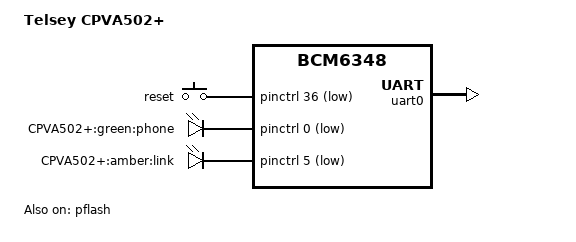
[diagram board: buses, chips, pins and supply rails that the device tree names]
/dts-v1/;

#include "bcm6348.dtsi"

#include <dt-bindings/input/input.h>

/ {
	model = "Telsey CPVA502+";
	compatible = "telsey,cpva502+", "brcm,bcm6348";

	chosen {
		bootargs = "root=/dev/mtdblock2 rootfstype=squashfs,jffs2 noinitrd console=ttyS0,115200";
		stdout-path = "serial0:115200n8";
	};

	gpio-keys-polled {
		compatible = "gpio-keys-polled";
		#address-cells = <1>;
		#size-cells = <0>;
		poll-interval = <20>;
		debounce-interval = <60>;

		reset {
			label = "reset";
			gpios = <&pinctrl 36 1>;
			linux,code = <KEY_RESTART>;
		};
	};

	gpio-leds {
		compatible = "gpio-leds";

		phone_green {
			label = "CPVA502+:green:phone";
			gpios = <&pinctrl 0 1>;
		};

		link_amber {
			label = "CPVA502+:amber:link";
			gpios = <&pinctrl 5 1>;
		};
	};
};

&pflash {
	status = "ok";

	linux,part-probe = "bcm63xxpart";

	cfe@0 {
		label = "CFE";
		reg = <0x000000 0x010000>;
		read-only;
	};

	linux@10000 {
		label = "linux";
		reg = <0x010000 0x3e0000>;
	};

	nvram@3f0000 {
		label = "nvram";
		reg = <0x3f0000 0x010000>;
	};
};

&pinctrl {
	pinctrl-names = "default";
	pinctrl-0 = <&pinctrl_pci &pinctrl_ext_mii>;
};

&uart0 {
	status = "ok";
};
